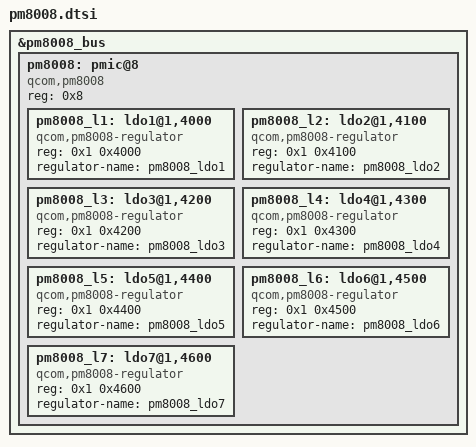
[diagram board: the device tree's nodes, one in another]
// SPDX-License-Identifier: BSD-3-Clause
// Copyright (c) 2022 Qualcomm Innovation Center, Inc. All rights reserved.

&pm8008_bus {
	pm8008: pmic@8 {
		compatible = "qcom,pm8008";
		reg = <0x8>;
		#address-cells = <2>;
		#size-cells = <0>;
		#interrupt-cells = <2>;

		pm8008_l1: ldo1@1,4000 {
			compatible = "qcom,pm8008-regulator";
			reg = <0x1 0x4000>;
			regulator-name = "pm8008_ldo1";
		};

		pm8008_l2: ldo2@1,4100 {
			compatible = "qcom,pm8008-regulator";
			reg = <0x1 0x4100>;
			regulator-name = "pm8008_ldo2";
		};

		pm8008_l3: ldo3@1,4200 {
			compatible = "qcom,pm8008-regulator";
			reg = <0x1 0x4200>;
			regulator-name = "pm8008_ldo3";
		};

		pm8008_l4: ldo4@1,4300 {
			compatible = "qcom,pm8008-regulator";
			reg = <0x1 0x4300>;
			regulator-name = "pm8008_ldo4";
		};

		pm8008_l5: ldo5@1,4400 {
			compatible = "qcom,pm8008-regulator";
			reg = <0x1 0x4400>;
			regulator-name = "pm8008_ldo5";
		};

		pm8008_l6: ldo6@1,4500 {
			compatible = "qcom,pm8008-regulator";
			reg = <0x1 0x4500>;
			regulator-name = "pm8008_ldo6";
		};

		pm8008_l7: ldo7@1,4600 {
			compatible = "qcom,pm8008-regulator";
			reg = <0x1 0x4600>;
			regulator-name = "pm8008_ldo7";
		};
	};
};
